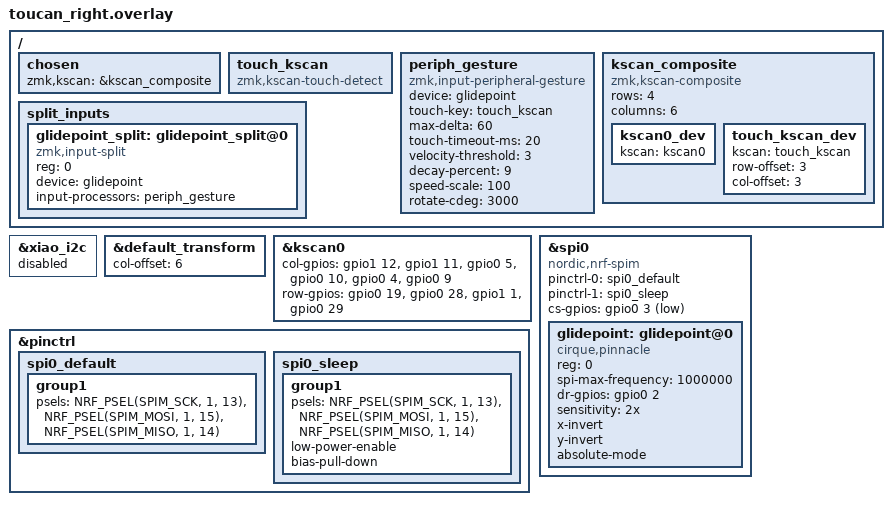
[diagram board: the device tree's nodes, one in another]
#include "toucan.dtsi"
#include <input/processors.dtsi>
#include <dt-bindings/zmk/input_transform.h>

&xiao_i2c {
    status = "disabled";
};

&default_transform {
    col-offset = <6>;
};

&kscan0 {
    col-gpios
    = <&gpio1 12 GPIO_ACTIVE_HIGH>
    , <&gpio1 11 GPIO_ACTIVE_HIGH>
    , <&gpio0 5 GPIO_ACTIVE_HIGH>
    , <&gpio0 10 GPIO_ACTIVE_HIGH>
    , <&gpio0 4 GPIO_ACTIVE_HIGH>
    , <&gpio0 9 GPIO_ACTIVE_HIGH>
    ;

    row-gpios
    = <&gpio0 19 (GPIO_ACTIVE_HIGH | GPIO_PULL_DOWN)>
    , <&gpio0 28 (GPIO_ACTIVE_HIGH | GPIO_PULL_DOWN)>
    , <&gpio1 1 (GPIO_ACTIVE_HIGH | GPIO_PULL_DOWN)>
    , <&gpio0 29 (GPIO_ACTIVE_HIGH | GPIO_PULL_DOWN)>
    ;
};

&pinctrl {
    spi0_default: spi0_default {
        group1 {
            psels = <NRF_PSEL(SPIM_SCK, 1, 13)>,
                <NRF_PSEL(SPIM_MOSI, 1, 15)>,
                <NRF_PSEL(SPIM_MISO, 1, 14)>;
        };
    };

     spi0_sleep: spi0_sleep {
        group1 {
            psels = <NRF_PSEL(SPIM_SCK, 1, 13)>,
                    <NRF_PSEL(SPIM_MOSI, 1, 15)>,
                    <NRF_PSEL(SPIM_MISO, 1, 14)>;
            low-power-enable;
            bias-pull-down; // minimize power leakage during sleep
        };
    };

};

&spi0 {
   compatible = "nordic,nrf-spim";
   status = "okay";
   pinctrl-0 = <&spi0_default>;
   pinctrl-1 = <&spi0_sleep>;
   pinctrl-names = "default", "sleep";
   cs-gpios = <&gpio0 3 (GPIO_ACTIVE_LOW | GPIO_PULL_UP)>;  // pull-up to ensure CS is !asserted when asleep
   glidepoint:  glidepoint@0 {
        compatible = "cirque,pinnacle";
        reg = <0>;
        spi-max-frequency = <1000000>;
        status = "okay";
        dr-gpios = <&gpio0 2 (GPIO_ACTIVE_HIGH)>;
        sensitivity = "2x";
        x-invert;
        y-invert;
        absolute-mode;

        // Optional: turning this on enables very aggressive power saving, after 5 seconds with no touches
        // the trackpad will go to sleep.  It wakes up on touch, but there is a ~300ms delay.  Most users will find
        // the standard behavior of 'put to sleep when zmk enters idle state (30 seconds without a keypress) feels better.
	    //sleep;
    };
};

/ {
    chosen {
        zmk,kscan = &kscan_composite;
    };

    touch_kscan: touch_kscan {
        compatible = "zmk,kscan-touch-detect";
        status = "okay";
    };

    periph_gesture: periph_gesture {
        compatible = "zmk,input-peripheral-gesture";
        #input-processor-cells = <0>;
        status = "okay";
        device = <&glidepoint>;
        touch-key = <&touch_kscan>;
        max-delta = <60>;
        touch-timeout-ms = <20>;
        velocity-threshold = <3>;
        decay-percent = <9>;
        speed-scale = <100>;
        rotate-cdeg = <3000>;
    };

    kscan_composite: kscan_composite {
        compatible = "zmk,kscan-composite";
        rows = <4>;
        columns = <6>;

        kscan0_dev {
            kscan = <&kscan0>;
        };

        touch_kscan_dev {
            kscan = <&touch_kscan>;
            row-offset = <3>;
            col-offset = <3>;
        };
    };

    split_inputs {
        #address-cells = <1>;
        #size-cells = <0>;

        glidepoint_split: glidepoint_split@0 {
            compatible = "zmk,input-split";
            reg = <0>;
            device = <&glidepoint>;
            input-processors = <&periph_gesture>;
        };
    };
};
